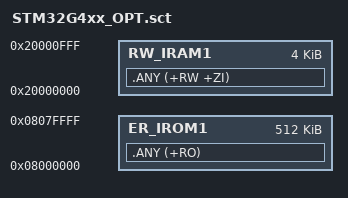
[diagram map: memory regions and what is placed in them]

LR_IROM1 0x08000000 0x00080000  {    ; load region size_region
  ER_IROM1 0x08000000 0x00080000  {  ; load address = execution address
   .ANY (+RO)
  }
  RW_IRAM1 0x20000000 0x00001000  {  ; RW data
   .ANY (+RW +ZI)
  }
}

; Note:
; Flash Option Bytes are placed at an absolte address. 
; Linker option --autoat is enabled by default so the linker
; generates a separate load reagon for the Flash Option Byte memory space.
